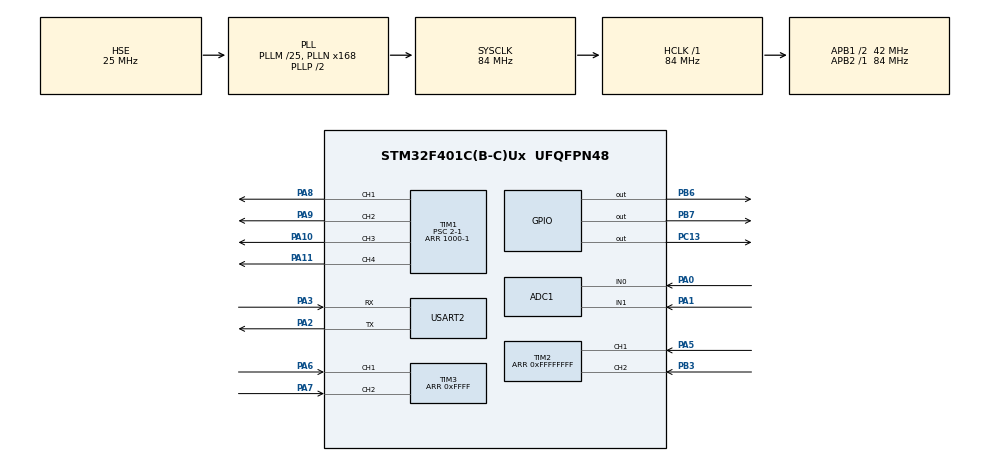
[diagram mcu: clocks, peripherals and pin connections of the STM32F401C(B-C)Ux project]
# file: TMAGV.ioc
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ADC1.Channel-2\#ChannelRegularConversion=ADC_CHANNEL_1
ADC1.NbrOfConversionFlag=1
ADC1.Rank-2\#ChannelRegularConversion=1
ADC1.SamplingTime-2\#ChannelRegularConversion=ADC_SAMPLETIME_3CYCLES
ADC1.master=1
Mcu.Family=STM32F4
Mcu.Name=STM32F401C(B-C)Ux
Mcu.Package=UFQFPN48
NVIC.PriorityGroup=NVIC_PRIORITYGROUP_4
NVIC.TIM1_TRG_COM_TIM11_IRQn=true\:0\:0\:false\:false\:true\:true\:true
NVIC.USART2_IRQn=true\:0\:0\:false\:false\:true\:true\:true
PA0-WKUP.Signal=ADCx_IN0
PA1.Signal=ADCx_IN1
PA10.GPIO_Speed=GPIO_SPEED_FREQ_VERY_HIGH
PA10.Signal=S_TIM1_CH3
PA11.GPIO_Speed=GPIO_SPEED_FREQ_VERY_HIGH
PA11.Signal=S_TIM1_CH4
PA2.Mode=Asynchronous
PA2.Signal=USART2_TX
PA3.Mode=Asynchronous
PA3.Signal=USART2_RX
PA5.GPIO_Speed=GPIO_SPEED_FREQ_VERY_HIGH
PA5.Signal=S_TIM2_CH1_ETR
PA6.GPIO_Speed=GPIO_SPEED_FREQ_VERY_HIGH
PA6.Signal=S_TIM3_CH1
PA7.GPIO_Speed=GPIO_SPEED_FREQ_VERY_HIGH
PA7.Signal=S_TIM3_CH2
PA8.Signal=S_TIM1_CH1
PA9.GPIO_Speed=GPIO_SPEED_FREQ_VERY_HIGH
PA9.Signal=S_TIM1_CH2
PB3.GPIO_Speed=GPIO_SPEED_FREQ_VERY_HIGH
PB3.Signal=S_TIM2_CH2
PB6.GPIO_ModeDefaultOutputPP=GPIO_MODE_OUTPUT_OD
PB6.GPIO_Speed=GPIO_SPEED_FREQ_VERY_HIGH
PB6.PinState=GPIO_PIN_SET
PB6.Signal=GPIO_Output
PB7.GPIO_ModeDefaultOutputPP=GPIO_MODE_OUTPUT_OD
PB7.GPIO_Speed=GPIO_SPEED_FREQ_VERY_HIGH
PB7.PinState=GPIO_PIN_SET
PB7.Signal=GPIO_Output
PC13-ANTI_TAMP.Signal=GPIO_Output
PC14-OSC32_IN.Mode=LSE-External-Oscillator
PC14-OSC32_IN.Signal=RCC_OSC32_IN
PC15-OSC32_OUT.Mode=LSE-External-Oscillator
PC15-OSC32_OUT.Signal=RCC_OSC32_OUT
PH0\ -\ OSC_IN.Mode=HSE-External-Oscillator
PH0\ -\ OSC_IN.Signal=RCC_OSC_IN
PH1\ -\ OSC_OUT.Mode=HSE-External-Oscillator
PH1\ -\ OSC_OUT.Signal=RCC_OSC_OUT
ProjectManager.HeapSize=0x200
ProjectManager.StackSize=0x400
ProjectManager.TargetToolchain=MDK-ARM V5.27
RCC.48MHZClocksFreq_Value=42000000
RCC.AHBFreq_Value=84000000
RCC.APB1CLKDivider=RCC_HCLK_DIV2
RCC.APB1Freq_Value=42000000
RCC.APB1TimFreq_Value=84000000
RCC.APB2Freq_Value=84000000
RCC.APB2TimFreq_Value=84000000
RCC.CortexFreq_Value=84000000
RCC.HCLKFreq_Value=84000000
RCC.HSE_VALUE=25000000
RCC.HSI_VALUE=16000000
RCC.PLLM=25
RCC.PLLN=168
RCC.PLLSourceVirtual=RCC_PLLSOURCE_HSE
RCC.SYSCLKFreq_VALUE=84000000
RCC.SYSCLKSource=RCC_SYSCLKSOURCE_PLLCLK
RCC.VCOOutputFreq_Value=168000000
SH.ADCx_IN0.0=ADC1_IN0,IN0
SH.ADCx_IN1.0=ADC1_IN1,IN1
SH.S_TIM1_CH1.0=TIM1_CH1,PWM Generation1 CH1
SH.S_TIM1_CH2.0=TIM1_CH2,PWM Generation2 CH2
SH.S_TIM1_CH3.0=TIM1_CH3,PWM Generation3 CH3
SH.S_TIM1_CH4.0=TIM1_CH4,PWM Generation4 CH4
SH.S_TIM2_CH1_ETR.0=TIM2_CH1,Encoder_Interface
SH.S_TIM2_CH2.0=TIM2_CH2,Encoder_Interface
SH.S_TIM3_CH1.0=TIM3_CH1,Encoder_Interface
SH.S_TIM3_CH2.0=TIM3_CH2,Encoder_Interface
TIM1.Channel-PWM\ Generation1\ CH1=TIM_CHANNEL_1
TIM1.Channel-PWM\ Generation2\ CH2=TIM_CHANNEL_2
TIM1.Channel-PWM\ Generation3\ CH3=TIM_CHANNEL_3
TIM1.Channel-PWM\ Generation4\ CH4=TIM_CHANNEL_4
TIM1.Period=1000-1
TIM1.Prescaler=2-1
TIM11.Period=1000
TIM11.Prescaler=84-1
TIM2.IC1Filter=15
TIM2.IC2Filter=15
TIM2.Period=0xFFFFFFFF
TIM3.IC1Filter=15
TIM3.IC2Filter=15
TIM3.Period=0xFFFF
USART2.VirtualMode=VM_ASYNC
VP_TIM11_VS_ClockSourceINT.Mode=Enable_Timer
VP_TIM1_VS_ClockSourceINT.Mode=Internal
board=custom

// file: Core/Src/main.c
/* USER CODE BEGIN Header */
/**
  ******************************************************************************
  * @file           : main.c
  * @brief          : Main program body
  ******************************************************************************
  * @attention
  *
  * <h2><center>&copy; Copyright (c) 2019 STMicroelectronics.
  * All rights reserved.</center></h2>
  *
  * This software component is licensed by ST under BSD 3-Clause license,
  * the "License"; You may not use this file except in compliance with the
  * License. You may obtain a copy of the License at:
  *                        opensource.org/licenses/BSD-3-Clause
  *
  ******************************************************************************
  */
/* USER CODE END Header */

#include "main.h"
#include "adc.h"
#include "tim.h"
#include "usart.h"
#include "gpio.h"

/* USER CODE BEGIN Includes */
#include "tmagv.h"
/* USER CODE END Includes */

void SystemClock_Config(void);

int main(void)
{

  /* MCU Configuration--------------------------------------------------------*/

  /* Reset of all peripherals, Initializes the Flash interface and the Systick. */
  HAL_Init();

  /* Configure the system clock */
  SystemClock_Config();

  /* Initialize all configured peripherals */
  MX_GPIO_Init();
  MX_ADC1_Init();
  MX_TIM1_Init();
  MX_TIM2_Init();
  MX_TIM3_Init();
  MX_USART2_UART_Init();
  MX_TIM11_Init();
  /* USER CODE BEGIN 2 */
	TMAGV_Setup();
  /* USER CODE END 2 */

  /* Infinite loop */
  while (1)
  {

    /* USER CODE BEGIN 3 */
		TMAGV_Loop();

  }
  /* USER CODE END 3 */
}

void SystemClock_Config(void)
{
  RCC_OscInitTypeDef RCC_OscInitStruct = {0};
  RCC_ClkInitTypeDef RCC_ClkInitStruct = {0};

  /** Configure the main internal regulator output voltage
  */
  __HAL_RCC_PWR_CLK_ENABLE();
  __HAL_PWR_VOLTAGESCALING_CONFIG(PWR_REGULATOR_VOLTAGE_SCALE2);
  /** Initializes the CPU, AHB and APB busses clocks
  */
  RCC_OscInitStruct.OscillatorType = RCC_OSCILLATORTYPE_HSE;
  RCC_OscInitStruct.HSEState = RCC_HSE_ON;
  RCC_OscInitStruct.PLL.PLLState = RCC_PLL_ON;
  RCC_OscInitStruct.PLL.PLLSource = RCC_PLLSOURCE_HSE;
  RCC_OscInitStruct.PLL.PLLM = 25;
  RCC_OscInitStruct.PLL.PLLN = 168;
  RCC_OscInitStruct.PLL.PLLP = RCC_PLLP_DIV2;
  RCC_OscInitStruct.PLL.PLLQ = 4;
  if (HAL_RCC_OscConfig(&RCC_OscInitStruct) != HAL_OK)
  {
    Error_Handler();
  }
  /** Initializes the CPU, AHB and APB busses clocks
  */
  RCC_ClkInitStruct.ClockType = RCC_CLOCKTYPE_HCLK|RCC_CLOCKTYPE_SYSCLK
                              |RCC_CLOCKTYPE_PCLK1|RCC_CLOCKTYPE_PCLK2;
  RCC_ClkInitStruct.SYSCLKSource = RCC_SYSCLKSOURCE_PLLCLK;
  RCC_ClkInitStruct.AHBCLKDivider = RCC_SYSCLK_DIV1;
  RCC_ClkInitStruct.APB1CLKDivider = RCC_HCLK_DIV2;
  RCC_ClkInitStruct.APB2CLKDivider = RCC_HCLK_DIV1;

  if (HAL_RCC_ClockConfig(&RCC_ClkInitStruct, FLASH_LATENCY_2) != HAL_OK)
  {
    Error_Handler();
  }
}

void Error_Handler(void)
{
}

/************************ (C) COPYRIGHT STMicroelectronics *****END OF FILE****/
